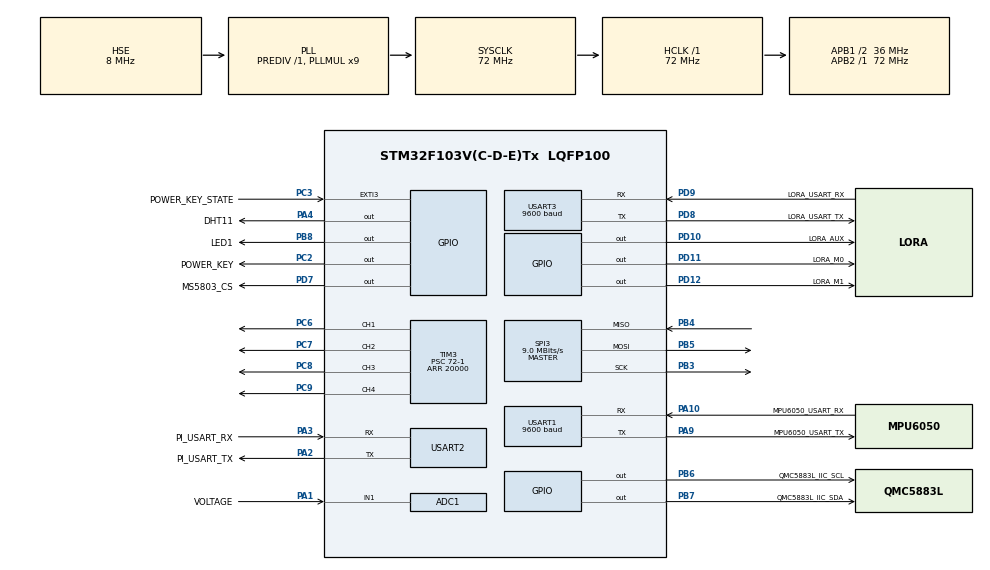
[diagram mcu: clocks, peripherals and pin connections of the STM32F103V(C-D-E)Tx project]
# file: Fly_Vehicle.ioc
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ADC1.Channel-0\#ChannelRegularConversion=ADC_CHANNEL_1
ADC1.ContinuousConvMode=ENABLE
ADC1.InjNumberOfConversion=0
ADC1.NbrOfConversion=1
ADC1.NbrOfConversionFlag=1
ADC1.Rank-0\#ChannelRegularConversion=1
ADC1.SamplingTime-0\#ChannelRegularConversion=ADC_SAMPLETIME_239CYCLES_5
ADC1.master=1
Dma.ADC1.2.Direction=DMA_PERIPH_TO_MEMORY
Dma.ADC1.2.Instance=DMA1_Channel1
Dma.ADC1.2.MemDataAlignment=DMA_MDATAALIGN_WORD
Dma.ADC1.2.MemInc=DMA_MINC_ENABLE
Dma.ADC1.2.Mode=DMA_CIRCULAR
Dma.ADC1.2.PeriphDataAlignment=DMA_PDATAALIGN_WORD
Dma.ADC1.2.PeriphInc=DMA_PINC_DISABLE
Dma.ADC1.2.Priority=DMA_PRIORITY_LOW
Dma.Request0=USART1_RX
Dma.Request1=USART3_RX
Dma.Request2=ADC1
Dma.Request3=USART2_RX
Dma.Request4=USART2_TX
Dma.USART1_RX.0.Direction=DMA_PERIPH_TO_MEMORY
Dma.USART1_RX.0.Instance=DMA1_Channel5
Dma.USART1_RX.0.MemDataAlignment=DMA_MDATAALIGN_BYTE
Dma.USART1_RX.0.MemInc=DMA_MINC_ENABLE
Dma.USART1_RX.0.Mode=DMA_CIRCULAR
Dma.USART1_RX.0.PeriphDataAlignment=DMA_PDATAALIGN_BYTE
Dma.USART1_RX.0.PeriphInc=DMA_PINC_DISABLE
Dma.USART1_RX.0.Priority=DMA_PRIORITY_LOW
Dma.USART2_RX.3.Direction=DMA_PERIPH_TO_MEMORY
Dma.USART2_RX.3.Instance=DMA1_Channel6
Dma.USART2_RX.3.MemDataAlignment=DMA_MDATAALIGN_BYTE
Dma.USART2_RX.3.MemInc=DMA_MINC_ENABLE
Dma.USART2_RX.3.Mode=DMA_CIRCULAR
Dma.USART2_RX.3.PeriphDataAlignment=DMA_PDATAALIGN_BYTE
Dma.USART2_RX.3.PeriphInc=DMA_PINC_DISABLE
Dma.USART2_RX.3.Priority=DMA_PRIORITY_LOW
Dma.USART2_TX.4.Direction=DMA_MEMORY_TO_PERIPH
Dma.USART2_TX.4.Instance=DMA1_Channel7
Dma.USART2_TX.4.MemDataAlignment=DMA_MDATAALIGN_BYTE
Dma.USART2_TX.4.MemInc=DMA_MINC_ENABLE
Dma.USART2_TX.4.Mode=DMA_NORMAL
Dma.USART2_TX.4.PeriphDataAlignment=DMA_PDATAALIGN_BYTE
Dma.USART2_TX.4.PeriphInc=DMA_PINC_DISABLE
Dma.USART2_TX.4.Priority=DMA_PRIORITY_LOW
Dma.USART3_RX.1.Direction=DMA_PERIPH_TO_MEMORY
Dma.USART3_RX.1.Instance=DMA1_Channel3
Dma.USART3_RX.1.MemDataAlignment=DMA_MDATAALIGN_BYTE
Dma.USART3_RX.1.MemInc=DMA_MINC_ENABLE
Dma.USART3_RX.1.Mode=DMA_CIRCULAR
Dma.USART3_RX.1.PeriphDataAlignment=DMA_PDATAALIGN_BYTE
Dma.USART3_RX.1.PeriphInc=DMA_PINC_DISABLE
Dma.USART3_RX.1.Priority=DMA_PRIORITY_LOW
FREERTOS.INCLUDE_vTaskDelayUntil=1
FREERTOS.Tasks01=messageTask,0,500,message_Task_Function,As weak,NULL,Dynamic,NULL,NULL;sensorTask,-3,128,sensor_Task_Function,As weak,NULL,Dynamic,NULL,NULL;controlTask,-3,128,control_Task_Function,As weak,NULL,Dynamic,NULL,NULL;imuTask,-3,128,imu_Task_Function,As weak,NULL,Dynamic,NULL,NULL;ledTask,-3,128,led_Task_Function,As weak,NULL,Dynamic,NULL,NULL;pressureTask,2,128,pressure_Task_Function,As weak,NULL,Dynamic,NULL,NULL
FREERTOS.configTOTAL_HEAP_SIZE=8192
Mcu.Family=STM32F1
Mcu.Name=STM32F103V(C-D-E)Tx
Mcu.Package=LQFP100
NVIC.DMA1_Channel1_IRQn=true\:5\:0\:false\:false\:true\:true\:false\:true
NVIC.DMA1_Channel3_IRQn=true\:5\:0\:false\:false\:true\:true\:false\:true
NVIC.DMA1_Channel5_IRQn=true\:5\:0\:false\:false\:true\:true\:false\:true
NVIC.DMA1_Channel6_IRQn=true\:5\:0\:false\:false\:true\:true\:false\:true
NVIC.DMA1_Channel7_IRQn=true\:5\:0\:false\:false\:true\:true\:false\:true
NVIC.EXTI3_IRQn=true\:5\:0\:false\:false\:true\:true\:true\:true
NVIC.PriorityGroup=NVIC_PRIORITYGROUP_4
NVIC.SPI3_IRQn=true\:5\:0\:false\:false\:true\:true\:true\:true
NVIC.TIM7_IRQn=true\:0\:0\:false\:false\:true\:false\:false\:true
NVIC.TimeBase=TIM7_IRQn
NVIC.TimeBaseIP=TIM7
NVIC.USART1_IRQn=true\:5\:0\:false\:false\:true\:true\:true\:true
NVIC.USART2_IRQn=true\:5\:0\:false\:false\:true\:true\:true\:true
NVIC.USART3_IRQn=true\:5\:0\:false\:false\:true\:true\:true\:true
OSC_IN.Mode=HSE-External-Oscillator
OSC_IN.Signal=RCC_OSC_IN
OSC_OUT.Mode=HSE-External-Oscillator
OSC_OUT.Signal=RCC_OSC_OUT
PA1.GPIO_Label=VOLTAGE
PA1.Signal=ADCx_IN1
PA10.GPIO_Label=MPU6050_USART_RX
PA10.Mode=Asynchronous
PA10.Signal=USART1_RX
PA13.Mode=Serial_Wire
PA13.Signal=SYS_JTMS-SWDIO
PA14.Mode=Serial_Wire
PA14.Signal=SYS_JTCK-SWCLK
PA2.GPIO_Label=PI_USART_TX
PA2.Mode=Asynchronous
PA2.Signal=USART2_TX
PA3.GPIO_Label=PI_USART_RX
PA3.Mode=Asynchronous
PA3.Signal=USART2_RX
PA4.GPIO_Label=DHT11
PA4.GPIO_Speed=GPIO_SPEED_FREQ_HIGH
PA4.PinState=GPIO_PIN_SET
PA4.Signal=GPIO_Output
PA9.GPIO_Label=MPU6050_USART_TX
PA9.Mode=Asynchronous
PA9.Signal=USART1_TX
PB3.Mode=Full_Duplex_Master
PB3.Signal=SPI3_SCK
PB4.Mode=Full_Duplex_Master
PB4.Signal=SPI3_MISO
PB5.Mode=Full_Duplex_Master
PB5.Signal=SPI3_MOSI
PB6.GPIO_Label=QMC5883L_IIC_SCL
PB6.GPIO_Speed=GPIO_SPEED_FREQ_HIGH
PB6.PinState=GPIO_PIN_SET
PB6.Signal=GPIO_Output
PB7.GPIO_Label=QMC5883L_IIC_SDA
PB7.GPIO_Speed=GPIO_SPEED_FREQ_HIGH
PB7.PinState=GPIO_PIN_SET
PB7.Signal=GPIO_Output
PB8.GPIO_Label=LED1
PB8.Signal=GPIO_Output
PC2.GPIO_Label=POWER_KEY
PC2.GPIO_PuPd=GPIO_NOPULL
PC2.PinState=GPIO_PIN_SET
PC2.Signal=GPIO_Output
PC3.GPIO_Label=POWER_KEY_STATE
PC3.GPIO_ModeDefaultEXTI=GPIO_MODE_IT_FALLING
PC3.Signal=GPXTI3
PC6.Signal=S_TIM3_CH1
PC7.Signal=S_TIM3_CH2
PC8.Signal=S_TIM3_CH3
PC9.Signal=S_TIM3_CH4
PD10.GPIO_Label=LORA_AUX
PD10.Signal=GPIO_Output
PD11.GPIO_Label=LORA_M0
PD11.Signal=GPIO_Output
PD12.GPIO_Label=LORA_M1
PD12.Signal=GPIO_Output
PD7.GPIO_Label=MS5803_CS
PD7.GPIO_PuPd=GPIO_PULLUP
PD7.GPIO_Speed=GPIO_SPEED_FREQ_HIGH
PD7.PinState=GPIO_PIN_SET
PD7.Signal=GPIO_Output
PD8.GPIO_Label=LORA_USART_TX
PD8.Mode=Asynchronous
PD8.Signal=USART3_TX
PD9.GPIO_Label=LORA_USART_RX
PD9.Mode=Asynchronous
PD9.Signal=USART3_RX
ProjectManager.HeapSize=0x200
ProjectManager.StackSize=0x400
ProjectManager.TargetToolchain=MDK-ARM V5
RCC.ADCPresc=RCC_ADCPCLK2_DIV6
RCC.AHBFreq_Value=72000000
RCC.APB1CLKDivider=RCC_HCLK_DIV2
RCC.APB1Freq_Value=36000000
RCC.APB1TimFreq_Value=72000000
RCC.APB2Freq_Value=72000000
RCC.APB2TimFreq_Value=72000000
RCC.HCLKFreq_Value=72000000
RCC.PLLMUL=RCC_PLL_MUL9
RCC.PLLSourceVirtual=RCC_PLLSOURCE_HSE
RCC.SYSCLKFreq_VALUE=72000000
RCC.SYSCLKSource=RCC_SYSCLKSOURCE_PLLCLK
RCC.USBFreq_Value=72000000
SH.ADCx_IN1.0=ADC1_IN1,IN1
SH.S_TIM3_CH1.0=TIM3_CH1,PWM Generation1 CH1
SH.S_TIM3_CH2.0=TIM3_CH2,PWM Generation2 CH2
SH.S_TIM3_CH3.0=TIM3_CH3,PWM Generation3 CH3
SH.S_TIM3_CH4.0=TIM3_CH4,PWM Generation4 CH4
SPI3.BaudRatePrescaler=SPI_BAUDRATEPRESCALER_4
SPI3.CalculateBaudRate=9.0 MBits/s
SPI3.Direction=SPI_DIRECTION_2LINES
SPI3.Mode=SPI_MODE_MASTER
SPI3.VirtualType=VM_MASTER
TIM3.Channel-PWM\ Generation1\ CH1=TIM_CHANNEL_1
TIM3.Channel-PWM\ Generation2\ CH2=TIM_CHANNEL_2
TIM3.Channel-PWM\ Generation3\ CH3=TIM_CHANNEL_3
TIM3.Channel-PWM\ Generation4\ CH4=TIM_CHANNEL_4
TIM3.Period=20000
TIM3.Prescaler=72-1
TIM3.Pulse-PWM\ Generation1\ CH1=1500
TIM3.Pulse-PWM\ Generation2\ CH2=1500
TIM3.Pulse-PWM\ Generation3\ CH3=1500
TIM3.Pulse-PWM\ Generation4\ CH4=1500
TIM6.Period=1
TIM6.Prescaler=72-1
USART1.BaudRate=9600
USART1.VirtualMode=VM_ASYNC
USART2.VirtualMode=VM_ASYNC
USART3.BaudRate=9600
USART3.VirtualMode=VM_ASYNC
VP_FREERTOS_VS_CMSIS_V1.Mode=CMSIS_V1
VP_SYS_VS_tim7.Mode=TIM7
VP_TIM6_VS_ClockSourceINT.Mode=Enable_Timer
board=custom

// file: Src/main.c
/* USER CODE BEGIN Header */
/**
  ******************************************************************************
  * @file           : main.c
  * @brief          : Main program body
  ******************************************************************************
  * @attention
  *
  * <h2><center>&copy; Copyright (c) 2019 STMicroelectronics.
  * All rights reserved.</center></h2>
  *
  * This software component is licensed by ST under Ultimate Liberty license
  * SLA0044, the "License"; You may not use this file except in compliance with
  * the License. You may obtain a copy of the License at:
  *                             www.st.com/SLA0044
  *
  ******************************************************************************
  */
/* USER CODE END Header */

#include "main.h"
#include "cmsis_os.h"
#include "adc.h"
#include "dma.h"
#include "spi.h"
#include "tim.h"
#include "usart.h"
#include "gpio.h"

/* USER CODE BEGIN Includes */
#include "includes.h"
/* USER CODE END Includes */

/* USER CODE BEGIN PV */

//uint8_t power_key_sta;
/* USER CODE END PV */

void SystemClock_Config(void);
void MX_FREERTOS_Init(void);

int main(void)
{

  /* MCU Configuration--------------------------------------------------------*/

  /* Reset of all peripherals, Initializes the Flash interface and the Systick. */
  HAL_Init();

  /* Configure the system clock */
  SystemClock_Config();

  /* Initialize all configured peripherals */
  MX_GPIO_Init();
  MX_DMA_Init();
  MX_ADC1_Init();
  MX_TIM3_Init();
  MX_USART1_UART_Init();
  MX_USART2_UART_Init();
  MX_USART3_UART_Init();
  MX_TIM6_Init();
  MX_SPI3_Init();
  /* USER CODE BEGIN 2 */
  BSP_Init();
  /* USER CODE END 2 */

  /* Call init function for freertos objects (in freertos.c) */
  MX_FREERTOS_Init();
  /* Start scheduler */
  osKernelStart();

  /* We should never get here as control is now taken by the scheduler */
  /* Infinite loop */
  while (1)
  {

  }
}

void SystemClock_Config(void)
{
  RCC_OscInitTypeDef RCC_OscInitStruct = {0};
  RCC_ClkInitTypeDef RCC_ClkInitStruct = {0};
  RCC_PeriphCLKInitTypeDef PeriphClkInit = {0};

  /** Initializes the CPU, AHB and APB busses clocks
  */
  RCC_OscInitStruct.OscillatorType = RCC_OSCILLATORTYPE_HSE;
  RCC_OscInitStruct.HSEState = RCC_HSE_ON;
  RCC_OscInitStruct.HSEPredivValue = RCC_HSE_PREDIV_DIV1;
  RCC_OscInitStruct.HSIState = RCC_HSI_ON;
  RCC_OscInitStruct.PLL.PLLState = RCC_PLL_ON;
  RCC_OscInitStruct.PLL.PLLSource = RCC_PLLSOURCE_HSE;
  RCC_OscInitStruct.PLL.PLLMUL = RCC_PLL_MUL9;
  if (HAL_RCC_OscConfig(&RCC_OscInitStruct) != HAL_OK)
  {
    Error_Handler();
  }
  /** Initializes the CPU, AHB and APB busses clocks
  */
  RCC_ClkInitStruct.ClockType = RCC_CLOCKTYPE_HCLK|RCC_CLOCKTYPE_SYSCLK
                              |RCC_CLOCKTYPE_PCLK1|RCC_CLOCKTYPE_PCLK2;
  RCC_ClkInitStruct.SYSCLKSource = RCC_SYSCLKSOURCE_PLLCLK;
  RCC_ClkInitStruct.AHBCLKDivider = RCC_SYSCLK_DIV1;
  RCC_ClkInitStruct.APB1CLKDivider = RCC_HCLK_DIV2;
  RCC_ClkInitStruct.APB2CLKDivider = RCC_HCLK_DIV1;

  if (HAL_RCC_ClockConfig(&RCC_ClkInitStruct, FLASH_LATENCY_2) != HAL_OK)
  {
    Error_Handler();
  }
  PeriphClkInit.PeriphClockSelection = RCC_PERIPHCLK_ADC;
  PeriphClkInit.AdcClockSelection = RCC_ADCPCLK2_DIV6;
  if (HAL_RCCEx_PeriphCLKConfig(&PeriphClkInit) != HAL_OK)
  {
    Error_Handler();
  }
}

 /**
  * @brief  Period elapsed callback in non blocking mode
  * @note   This function is called  when TIM7 interrupt took place, inside
  * HAL_TIM_IRQHandler(). It makes a direct call to HAL_IncTick() to increment
  * a global variable "uwTick" used as application time base.
  * @param  htim : TIM handle
  * @retval None
  */
void HAL_TIM_PeriodElapsedCallback(TIM_HandleTypeDef *htim)
{
  if (htim->Instance == TIM7) {
    HAL_IncTick();
  }
}

void Error_Handler(void)
{
}

/************************ (C) COPYRIGHT STMicroelectronics *****END OF FILE****/

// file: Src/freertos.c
/* USER CODE BEGIN Header */
/**
  ******************************************************************************
  * File Name          : freertos.c
  * Description        : Code for freertos applications
  ******************************************************************************
  * @attention
  *
  * <h2><center>&copy; Copyright (c) 2019 STMicroelectronics.
  * All rights reserved.</center></h2>
  *
  * This software component is licensed by ST under Ultimate Liberty license
  * SLA0044, the "License"; You may not use this file except in compliance with
  * the License. You may obtain a copy of the License at:
  *                             www.st.com/SLA0044
  *
  ******************************************************************************
  */
/* USER CODE END Header */

#include "FreeRTOS.h"
#include "task.h"
#include "main.h"
#include "cmsis_os.h"

/* USER CODE BEGIN Includes */
#include "includes.h"
/* USER CODE END Includes */

osThreadId messageTaskHandle;
osThreadId sensorTaskHandle;
osThreadId controlTaskHandle;
osThreadId imuTaskHandle;
osThreadId ledTaskHandle;
osThreadId pressureTaskHandle;

void message_Task_Function(void const * argument);
void sensor_Task_Function(void const * argument);
void control_Task_Function(void const * argument);
void imu_Task_Function(void const * argument);
void led_Task_Function(void const * argument);
void pressure_Task_Function(void const * argument);

void MX_FREERTOS_Init(void); /* (MISRA C 2004 rule 8.1) */

/* GetIdleTaskMemory prototype (linked to static allocation support) */
void vApplicationGetIdleTaskMemory( StaticTask_t **ppxIdleTaskTCBBuffer, StackType_t **ppxIdleTaskStackBuffer, uint32_t *pulIdleTaskStackSize );

/* USER CODE BEGIN GET_IDLE_TASK_MEMORY */
static StaticTask_t xIdleTaskTCBBuffer;
static StackType_t xIdleStack[configMINIMAL_STACK_SIZE];

void vApplicationGetIdleTaskMemory( StaticTask_t **ppxIdleTaskTCBBuffer, StackType_t **ppxIdleTaskStackBuffer, uint32_t *pulIdleTaskStackSize )
{
  *ppxIdleTaskTCBBuffer = &xIdleTaskTCBBuffer;
  *ppxIdleTaskStackBuffer = &xIdleStack[0];
  *pulIdleTaskStackSize = configMINIMAL_STACK_SIZE;
  /* place for user code */
}
/* USER CODE END GET_IDLE_TASK_MEMORY */

void MX_FREERTOS_Init(void) {

  /* USER CODE BEGIN RTOS_QUEUES */
  /* add queues, ... */
  Task_Queue_Semaphore_Timers_Create();
  /* USER CODE END RTOS_QUEUES */

  /* Create the thread(s) */
  /* definition and creation of messageTask */
  osThreadDef(messageTask, message_Task_Function, osPriorityNormal, 0, 500);
  messageTaskHandle = osThreadCreate(osThread(messageTask), NULL);

  /* definition and creation of sensorTask */
  osThreadDef(sensorTask, sensor_Task_Function, osPriorityIdle, 0, 128);
  sensorTaskHandle = osThreadCreate(osThread(sensorTask), NULL);

  /* definition and creation of controlTask */
  osThreadDef(controlTask, control_Task_Function, osPriorityIdle, 0, 128);
  controlTaskHandle = osThreadCreate(osThread(controlTask), NULL);

  /* definition and creation of imuTask */
  osThreadDef(imuTask, imu_Task_Function, osPriorityIdle, 0, 128);
  imuTaskHandle = osThreadCreate(osThread(imuTask), NULL);

  /* definition and creation of ledTask */
  osThreadDef(ledTask, led_Task_Function, osPriorityIdle, 0, 128);
  ledTaskHandle = osThreadCreate(osThread(ledTask), NULL);

  /* definition and creation of pressureTask */
  osThreadDef(pressureTask, pressure_Task_Function, osPriorityHigh, 0, 128);
  pressureTaskHandle = osThreadCreate(osThread(pressureTask), NULL);

}

__weak void message_Task_Function(void const * argument)
{
  for(;;)
  {
    osDelay(1);
  }
}

__weak void sensor_Task_Function(void const * argument)
{
  for(;;)
  {
    osDelay(1);
  }
}

__weak void control_Task_Function(void const * argument)
{
  /* USER CODE BEGIN control_Task_Function */
  /* Infinite loop */
  for(;;)
  {
		osDelay(1000);
  }
  /* USER CODE END control_Task_Function */
}

__weak void imu_Task_Function(void const * argument)
{
  /* USER CODE BEGIN imu_Task_Function */
  /* Infinite loop */
  for(;;)
  {
    osDelay(1000);
  }
  /* USER CODE END imu_Task_Function */
}

__weak void led_Task_Function(void const * argument)
{
  for(;;)
  {
    osDelay(1);
  }
}

__weak void pressure_Task_Function(void const * argument)
{
  for(;;)
  {
    osDelay(1);
  }
}

/************************ (C) COPYRIGHT STMicroelectronics *****END OF FILE****/
